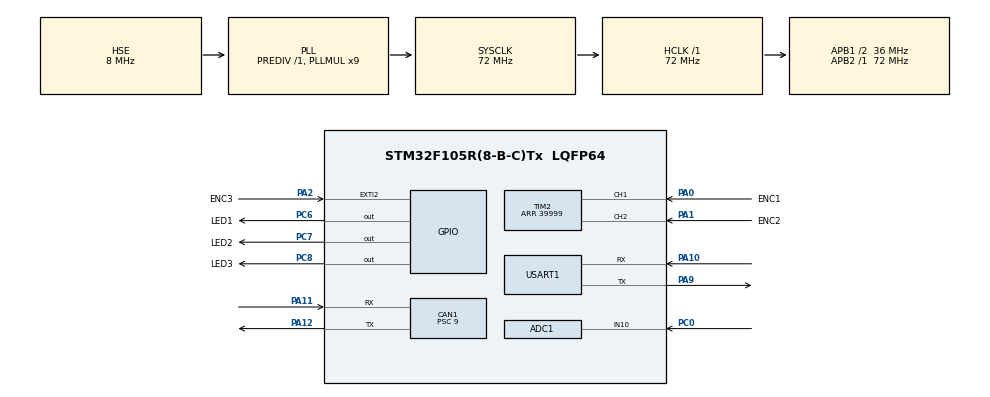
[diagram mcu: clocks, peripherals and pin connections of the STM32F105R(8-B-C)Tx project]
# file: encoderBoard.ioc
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ADC1.Channel-5\#ChannelRegularConversion=ADC_CHANNEL_10
ADC1.NbrOfConversionFlag=1
ADC1.Rank-5\#ChannelRegularConversion=1
ADC1.SamplingTime-5\#ChannelRegularConversion=ADC_SAMPLETIME_1CYCLE_5
ADC1.master=1
CAN1.BS1=CAN_BS1_13TQ
CAN1.BS2=CAN_BS2_2TQ
CAN1.CalculateTimeBit=4000
CAN1.CalculateTimeQuantum=250.0
CAN1.Prescaler=9
Mcu.Family=STM32F1
Mcu.Name=STM32F105R(8-B-C)Tx
Mcu.Package=LQFP64
NVIC.ADC1_2_IRQn=true\:0\:0\:false\:false\:true\:true
NVIC.CAN1_RX0_IRQn=true\:0\:0\:false\:false\:true\:true
NVIC.CAN1_RX1_IRQn=true\:0\:0\:false\:false\:true\:true
NVIC.CAN1_SCE_IRQn=true\:0\:0\:false\:false\:true\:true
NVIC.CAN1_TX_IRQn=true\:0\:0\:false\:false\:true\:true
NVIC.EXTI2_IRQn=true\:5\:0\:true\:false\:true\:true
NVIC.PriorityGroup=NVIC_PRIORITYGROUP_4
PA0-WKUP.GPIO_Label=ENC1
PA0-WKUP.Signal=S_TIM2_CH1_ETR
PA1.GPIO_Label=ENC2
PA1.Signal=S_TIM2_CH2
PA10.Mode=Asynchronous
PA10.Signal=USART1_RX
PA11.Mode=Master
PA11.Signal=CAN1_RX
PA12.Mode=Master
PA12.Signal=CAN1_TX
PA13.Mode=Serial_Wire
PA13.Signal=SYS_JTMS-SWDIO
PA14.Mode=Serial_Wire
PA14.Signal=SYS_JTCK-SWCLK
PA2.GPIO_Label=ENC3
PA2.Signal=GPXTI2
PA9.Mode=Asynchronous
PA9.Signal=USART1_TX
PC0.Signal=ADCx_IN10
PC6.GPIO_Label=LED1
PC6.Signal=GPIO_Output
PC7.GPIO_Label=LED2
PC7.Signal=GPIO_Output
PC8.GPIO_Label=LED3
PC8.Signal=GPIO_Output
PD0-OSC_IN.Mode=HSE-External-Oscillator
PD0-OSC_IN.Signal=RCC_OSC_IN
PD1-OSC_OUT.Mode=HSE-External-Oscillator
PD1-OSC_OUT.Signal=RCC_OSC_OUT
ProjectManager.HeapSize=0x200
ProjectManager.StackSize=0x400
ProjectManager.TargetToolchain=Makefile
RCC.ADCPresc=RCC_ADCPCLK2_DIV6
RCC.AHBFreq_Value=72000000
RCC.APB1CLKDivider=RCC_HCLK_DIV2
RCC.APB1Freq_Value=36000000
RCC.APB1TimFreq_Value=72000000
RCC.APB2Freq_Value=72000000
RCC.APB2TimFreq_Value=72000000
RCC.HCLKFreq_Value=72000000
RCC.PLLMUL=RCC_PLL_MUL9
RCC.PLLSourceVirtual=RCC_PLLSOURCE_HSE
RCC.SYSCLKFreq_VALUE=72000000
RCC.SYSCLKSource=RCC_SYSCLKSOURCE_PLLCLK
RCC.USBFreq_Value=48000000
SH.ADCx_IN10.0=ADC1_IN10,IN10
SH.S_TIM2_CH1_ETR.0=TIM2_CH1,Encoder_Interface
SH.S_TIM2_CH2.0=TIM2_CH2,Encoder_Interface
TIM2.EncoderMode=TIM_ENCODERMODE_TI12
TIM2.Period=39999
USART1.VirtualMode=VM_ASYNC
board=encoderBoard

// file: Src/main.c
/**
  ******************************************************************************
  * @file           : main.c
  * @brief          : Main program body
  ******************************************************************************
  ** This notice applies to any and all portions of this file
  * that are not between comment pairs USER CODE BEGIN and
  * USER CODE END. Other portions of this file, whether
  * inserted by the user or by software development tools
  * are owned by their respective copyright owners.
  *
  * COPYRIGHT(c) 2018 STMicroelectronics
  *
  * Redistribution and use in source and binary forms, with or without modification,
  * are permitted provided that the following conditions are met:
  *   1. Redistributions of source code must retain the above copyright notice,
  *      this list of conditions and the following disclaimer.
  *   2. Redistributions in binary form must reproduce the above copyright notice,
  *      this list of conditions and the following disclaimer in the documentation
  *      and/or other materials provided with the distribution.
  *   3. Neither the name of STMicroelectronics nor the names of its contributors
  *      may be used to endorse or promote products derived from this software
  *      without specific prior written permission.
  *
  * THIS SOFTWARE IS PROVIDED BY THE COPYRIGHT HOLDERS AND CONTRIBUTORS "AS IS"
  * AND ANY EXPRESS OR IMPLIED WARRANTIES, INCLUDING, BUT NOT LIMITED TO, THE
  * IMPLIED WARRANTIES OF MERCHANTABILITY AND FITNESS FOR A PARTICULAR PURPOSE ARE
  * DISCLAIMED. IN NO EVENT SHALL THE COPYRIGHT HOLDER OR CONTRIBUTORS BE LIABLE
  * FOR ANY DIRECT, INDIRECT, INCIDENTAL, SPECIAL, EXEMPLARY, OR CONSEQUENTIAL
  * DAMAGES (INCLUDING, BUT NOT LIMITED TO, PROCUREMENT OF SUBSTITUTE GOODS OR
  * SERVICES; LOSS OF USE, DATA, OR PROFITS; OR BUSINESS INTERRUPTION) HOWEVER
  * CAUSED AND ON ANY THEORY OF LIABILITY, WHETHER IN CONTRACT, STRICT LIABILITY,
  * OR TORT (INCLUDING NEGLIGENCE OR OTHERWISE) ARISING IN ANY WAY OUT OF THE USE
  * OF THIS SOFTWARE, EVEN IF ADVISED OF THE POSSIBILITY OF SUCH DAMAGE.
  *
  ******************************************************************************
  */
#include "main.h"
#include "stm32f1xx_hal.h"

/* USER CODE BEGIN Includes */
#include "globals.h"
#include "usrMain.h"
/* USER CODE END Includes */

ADC_HandleTypeDef hadc1;

CAN_HandleTypeDef hcan1;

TIM_HandleTypeDef htim2;

UART_HandleTypeDef huart1;

/* USER CODE BEGIN PV */
/* Private variables ---------------------------------------------------------*/

/* USER CODE END PV */

void SystemClock_Config(void);
static void MX_GPIO_Init(void);
static void MX_CAN1_Init(void);
static void MX_USART1_UART_Init(void);
static void MX_ADC1_Init(void);
static void MX_TIM2_Init(void);

/* USER CODE BEGIN PFP */
/* Private function prototypes -----------------------------------------------*/

/* USER CODE END PFP */

int main(void)
{

  /* MCU Configuration----------------------------------------------------------*/

  /* Reset of all peripherals, Initializes the Flash interface and the Systick. */
  HAL_Init();

  /* Configure the system clock */
  SystemClock_Config();

  /* Initialize all configured peripherals */
  MX_GPIO_Init();
  MX_CAN1_Init();
  MX_USART1_UART_Init();
  MX_ADC1_Init();
  MX_TIM2_Init();
  /* USER CODE BEGIN 2 */

	adc1Handle = &hadc1;
	can1Handle = &hcan1;
	tim2Handle = &htim2;
	usrMain();
  /* USER CODE END 2 */

  /* Infinite loop */
  while (1)
  {

  }

}

void SystemClock_Config(void)
{

  RCC_OscInitTypeDef RCC_OscInitStruct;
  RCC_ClkInitTypeDef RCC_ClkInitStruct;
  RCC_PeriphCLKInitTypeDef PeriphClkInit;

    /**Initializes the CPU, AHB and APB busses clocks
    */
  RCC_OscInitStruct.OscillatorType = RCC_OSCILLATORTYPE_HSE;
  RCC_OscInitStruct.HSEState = RCC_HSE_ON;
  RCC_OscInitStruct.HSEPredivValue = RCC_HSE_PREDIV_DIV1;
  RCC_OscInitStruct.HSIState = RCC_HSI_ON;
  RCC_OscInitStruct.Prediv1Source = RCC_PREDIV1_SOURCE_HSE;
  RCC_OscInitStruct.PLL.PLLState = RCC_PLL_ON;
  RCC_OscInitStruct.PLL.PLLSource = RCC_PLLSOURCE_HSE;
  RCC_OscInitStruct.PLL.PLLMUL = RCC_PLL_MUL9;
  RCC_OscInitStruct.PLL2.PLL2State = RCC_PLL_NONE;
  if (HAL_RCC_OscConfig(&RCC_OscInitStruct) != HAL_OK)
  {
    _Error_Handler(__FILE__, __LINE__);
  }

    /**Initializes the CPU, AHB and APB busses clocks
    */
  RCC_ClkInitStruct.ClockType = RCC_CLOCKTYPE_HCLK|RCC_CLOCKTYPE_SYSCLK
                              |RCC_CLOCKTYPE_PCLK1|RCC_CLOCKTYPE_PCLK2;
  RCC_ClkInitStruct.SYSCLKSource = RCC_SYSCLKSOURCE_PLLCLK;
  RCC_ClkInitStruct.AHBCLKDivider = RCC_SYSCLK_DIV1;
  RCC_ClkInitStruct.APB1CLKDivider = RCC_HCLK_DIV2;
  RCC_ClkInitStruct.APB2CLKDivider = RCC_HCLK_DIV1;

  if (HAL_RCC_ClockConfig(&RCC_ClkInitStruct, FLASH_LATENCY_2) != HAL_OK)
  {
    _Error_Handler(__FILE__, __LINE__);
  }

  PeriphClkInit.PeriphClockSelection = RCC_PERIPHCLK_ADC;
  PeriphClkInit.AdcClockSelection = RCC_ADCPCLK2_DIV6;
  if (HAL_RCCEx_PeriphCLKConfig(&PeriphClkInit) != HAL_OK)
  {
    _Error_Handler(__FILE__, __LINE__);
  }

    /**Configure the Systick interrupt time
    */
  HAL_SYSTICK_Config(HAL_RCC_GetHCLKFreq()/1000);

    /**Configure the Systick
    */
  HAL_SYSTICK_CLKSourceConfig(SYSTICK_CLKSOURCE_HCLK);

    /**Configure the Systick interrupt time
    */
  __HAL_RCC_PLLI2S_ENABLE();

  /* SysTick_IRQn interrupt configuration */
  HAL_NVIC_SetPriority(SysTick_IRQn, 0, 0);
}

/* ADC1 init function */
static void MX_ADC1_Init(void)
{

  ADC_ChannelConfTypeDef sConfig;

    /**Common config
    */
  hadc1.Instance = ADC1;
  hadc1.Init.ScanConvMode = ADC_SCAN_DISABLE;
  hadc1.Init.ContinuousConvMode = DISABLE;
  hadc1.Init.DiscontinuousConvMode = DISABLE;
  hadc1.Init.ExternalTrigConv = ADC_SOFTWARE_START;
  hadc1.Init.DataAlign = ADC_DATAALIGN_RIGHT;
  hadc1.Init.NbrOfConversion = 1;
  if (HAL_ADC_Init(&hadc1) != HAL_OK)
  {
    _Error_Handler(__FILE__, __LINE__);
  }

    /**Configure Regular Channel
    */
  sConfig.Channel = ADC_CHANNEL_10;
  sConfig.Rank = ADC_REGULAR_RANK_1;
  sConfig.SamplingTime = ADC_SAMPLETIME_1CYCLE_5;
  if (HAL_ADC_ConfigChannel(&hadc1, &sConfig) != HAL_OK)
  {
    _Error_Handler(__FILE__, __LINE__);
  }

}

/* CAN1 init function */
static void MX_CAN1_Init(void)
{

  hcan1.Instance = CAN1;
  hcan1.Init.Prescaler = 9;
  hcan1.Init.Mode = CAN_MODE_NORMAL;
  hcan1.Init.SJW = CAN_SJW_1TQ;
  hcan1.Init.BS1 = CAN_BS1_13TQ;
  hcan1.Init.BS2 = CAN_BS2_2TQ;
  hcan1.Init.TTCM = DISABLE;
  hcan1.Init.ABOM = DISABLE;
  hcan1.Init.AWUM = DISABLE;
  hcan1.Init.NART = DISABLE;
  hcan1.Init.RFLM = DISABLE;
  hcan1.Init.TXFP = DISABLE;
  if (HAL_CAN_Init(&hcan1) != HAL_OK)
  {
    _Error_Handler(__FILE__, __LINE__);
  }

}

/* TIM2 init function */
static void MX_TIM2_Init(void)
{

  TIM_Encoder_InitTypeDef sConfig;
  TIM_MasterConfigTypeDef sMasterConfig;

  htim2.Instance = TIM2;
  htim2.Init.Prescaler = 0;
  htim2.Init.CounterMode = TIM_COUNTERMODE_UP;
  htim2.Init.Period = 39999;
  htim2.Init.ClockDivision = TIM_CLOCKDIVISION_DIV1;
  htim2.Init.AutoReloadPreload = TIM_AUTORELOAD_PRELOAD_DISABLE;
  sConfig.EncoderMode = TIM_ENCODERMODE_TI12;
  sConfig.IC1Polarity = TIM_ICPOLARITY_RISING;
  sConfig.IC1Selection = TIM_ICSELECTION_DIRECTTI;
  sConfig.IC1Prescaler = TIM_ICPSC_DIV1;
  sConfig.IC1Filter = 0;
  sConfig.IC2Polarity = TIM_ICPOLARITY_RISING;
  sConfig.IC2Selection = TIM_ICSELECTION_DIRECTTI;
  sConfig.IC2Prescaler = TIM_ICPSC_DIV1;
  sConfig.IC2Filter = 0;
  if (HAL_TIM_Encoder_Init(&htim2, &sConfig) != HAL_OK)
  {
    _Error_Handler(__FILE__, __LINE__);
  }

  sMasterConfig.MasterOutputTrigger = TIM_TRGO_RESET;
  sMasterConfig.MasterSlaveMode = TIM_MASTERSLAVEMODE_DISABLE;
  if (HAL_TIMEx_MasterConfigSynchronization(&htim2, &sMasterConfig) != HAL_OK)
  {
    _Error_Handler(__FILE__, __LINE__);
  }

}

/* USART1 init function */
static void MX_USART1_UART_Init(void)
{

  huart1.Instance = USART1;
  huart1.Init.BaudRate = 115200;
  huart1.Init.WordLength = UART_WORDLENGTH_8B;
  huart1.Init.StopBits = UART_STOPBITS_1;
  huart1.Init.Parity = UART_PARITY_NONE;
  huart1.Init.Mode = UART_MODE_TX_RX;
  huart1.Init.HwFlowCtl = UART_HWCONTROL_NONE;
  huart1.Init.OverSampling = UART_OVERSAMPLING_16;
  if (HAL_UART_Init(&huart1) != HAL_OK)
  {
    _Error_Handler(__FILE__, __LINE__);
  }

}

/** Configure pins as
        * Analog
        * Input
        * Output
        * EVENT_OUT
        * EXTI
*/
static void MX_GPIO_Init(void)
{

  GPIO_InitTypeDef GPIO_InitStruct;

  /* GPIO Ports Clock Enable */
  __HAL_RCC_GPIOD_CLK_ENABLE();
  __HAL_RCC_GPIOC_CLK_ENABLE();
  __HAL_RCC_GPIOA_CLK_ENABLE();

  /*Configure GPIO pin Output Level */
  HAL_GPIO_WritePin(GPIOC, LED1_Pin|LED2_Pin|LED3_Pin, GPIO_PIN_RESET);

  /*Configure GPIO pin : ENC3_Pin */
  GPIO_InitStruct.Pin = ENC3_Pin;
  GPIO_InitStruct.Mode = GPIO_MODE_IT_RISING;
  GPIO_InitStruct.Pull = GPIO_NOPULL;
  HAL_GPIO_Init(ENC3_GPIO_Port, &GPIO_InitStruct);

  /*Configure GPIO pins : LED1_Pin LED2_Pin LED3_Pin */
  GPIO_InitStruct.Pin = LED1_Pin|LED2_Pin|LED3_Pin;
  GPIO_InitStruct.Mode = GPIO_MODE_OUTPUT_PP;
  GPIO_InitStruct.Speed = GPIO_SPEED_FREQ_LOW;
  HAL_GPIO_Init(GPIOC, &GPIO_InitStruct);

  /* EXTI interrupt init*/
  HAL_NVIC_SetPriority(EXTI2_IRQn, 5, 0);
  HAL_NVIC_EnableIRQ(EXTI2_IRQn);

}

/* USER CODE BEGIN 4 */

void HAL_GPIO_EXTI_Callback(uint16_t GPIO_Pin)
{
  //if (GPIO_Pin == GPIO_PIN_2)
    interruptExternal2();
}

/* USER CODE END 4 */

void _Error_Handler(char *file, int line)
{
  while(1)
  {
  }
}

/************************ (C) COPYRIGHT STMicroelectronics *****END OF FILE****/
